# APM32F41x register map
File version: 1.0
CPU: CM4 r1p0, little endian, no MPU, no FPU, 3 interrupt priority bits
Registers are 32-bit, read-write, reset 0x0 unless marked. A register's access mark holds for its fields unless they carry their own. Offsets are from the block's base; [hi:lo] are bit positions; {n}, {i} and the like mark numbered series.

## DCI — Digital camera interface
Base 0x50050000
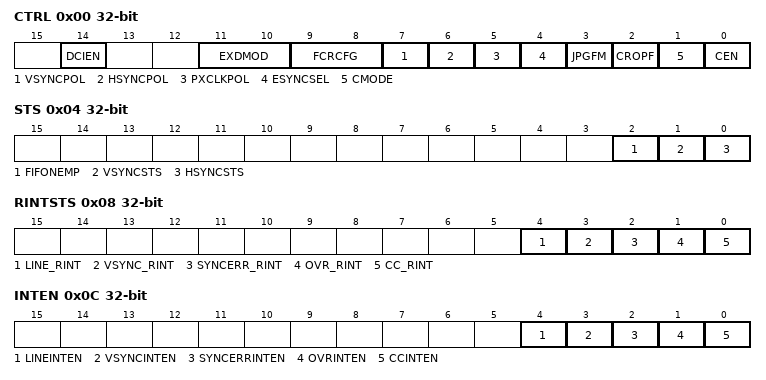
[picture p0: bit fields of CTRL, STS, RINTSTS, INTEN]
0x00 CTRL — control register 1
  [14] DCIEN — DCI enable
  [11:10] EXDMOD — Extended data mode
  [9:8] FCRCFG — Frame capture rate control
  [7] VSYNCPOL — Vertical synchronization polarity
  [6] HSYNCPOL — Horizontal synchronization polarity
  [5] PXCLKPOL — Pixel clock polarity
  [4] ESYNCSEL — Embedded synchronization select
  [3] JPGFM — JPEG format
  [2] CROPF — Crop feature
  [1] CMODE — Capture mode
  [0] CEN — Capture enable
0x04 STS ro — status register
  [2] FIFONEMP — FIFO not empty
  [1] VSYNCSTS
  [0] HSYNCSTS
0x08 RINTSTS ro — raw interrupt status register
  [4] LINE_RINT — Line raw interrupt status
  [3] VSYNC_RINT — VSYNC raw interrupt status
  [2] SYNCERR_RINT — Synchronization error raw interrupt status
  [1] OVR_RINT — Overrun raw interrupt status
  [0] CC_RINT — Capture complete raw interrupt status
0x0C INTEN — interrupt enable register
  [4] LINEINTEN — Line interrupt enable
  [3] VSYNCINTEN — VSYNC interrupt enable
  [2] SYNCERRINTEN — Synchronization error interrupt enable
  [1] OVRINTEN — Overrun interrupt enable
  [0] CCINTEN — Capture complete interrupt enable
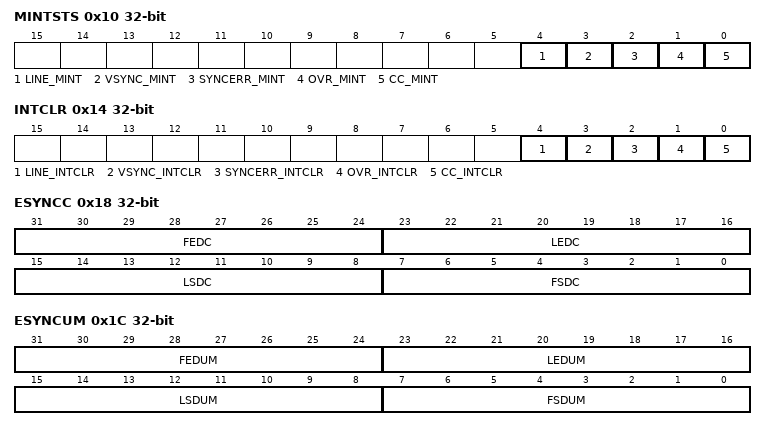
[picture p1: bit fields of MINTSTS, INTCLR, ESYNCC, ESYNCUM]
0x10 MINTSTS ro — masked interrupt status register
  [4] LINE_MINT — Line masked interrupt status
  [3] VSYNC_MINT — VSYNC masked interrupt status
  [2] SYNCERR_MINT — Synchronization error masked interrupt status
  [1] OVR_MINT — Overrun masked interrupt status
  [0] CC_MINT — Capture complete masked interrupt status
0x14 INTCLR wo — interrupt clear register
  [4] LINE_INTCLR — line interrupt status clear
  [3] VSYNC_INTCLR — Vertical synch interrupt status clear
  [2] SYNCERR_INTCLR — Synchronization error interrupt status clear
  [1] OVR_INTCLR — Overrun interrupt status clear
  [0] CC_INTCLR — Capture complete interrupt status clear
0x18 ESYNCC — embedded synchronization code register
  [31:24] FEDC — Frame end delimiter code
  [23:16] LEDC — Line end delimiter code
  [15:8] LSDC — Line start delimiter code
  [7:0] FSDC — Frame start delimiter code
0x1C ESYNCUM — embedded synchronization unmask register
  [31:24] FEDUM — Frame end delimiter unmask
  [23:16] LEDUM — Line end delimiter unmask
  [15:8] LSDUM — Line start delimiter unmask
  [7:0] FSDUM — Frame start delimiter unmask
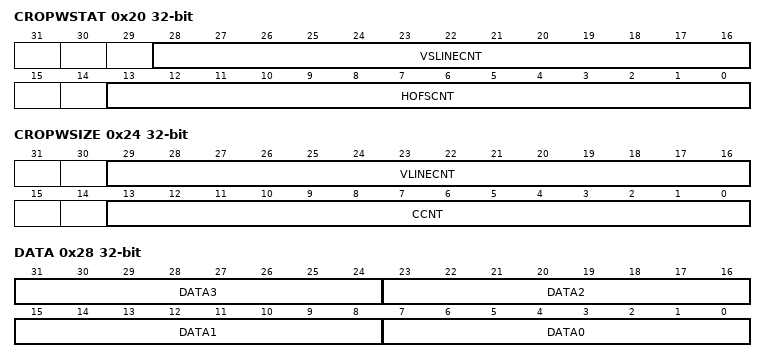
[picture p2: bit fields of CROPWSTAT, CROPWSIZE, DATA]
0x20 CROPWSTAT — crop window start
  [28:16] VSLINECNT — Vertical start line count
  [13:0] HOFSCNT — Horizontal offset count
0x24 CROPWSIZE — crop window size
  [29:16] VLINECNT — Vertical line count
  [13:0] CCNT — Capture count
0x28 DATA ro
  [8n+7:8n] DATA{n} (n=0..3) — Data byte {n}

## CRC — Cryptographic processor
Base 0x40023000
0x00 DATA reset 0xFFFFFFFF
0x04 INDATA — Independent Data register
  [7:0] INDATA
0x08 CTRL wo — Control register
  [0] RST — Reset CRC Calculation Unit

## GPIOI — General-purpose I/Os
Base 0x40022000
Same registers: GPIOC 0x40020800, GPIOD 0x40020C00, GPIOE 0x40021000, GPIOF 0x40021400, GPIOG 0x40021800, GPIOH 0x40021C00
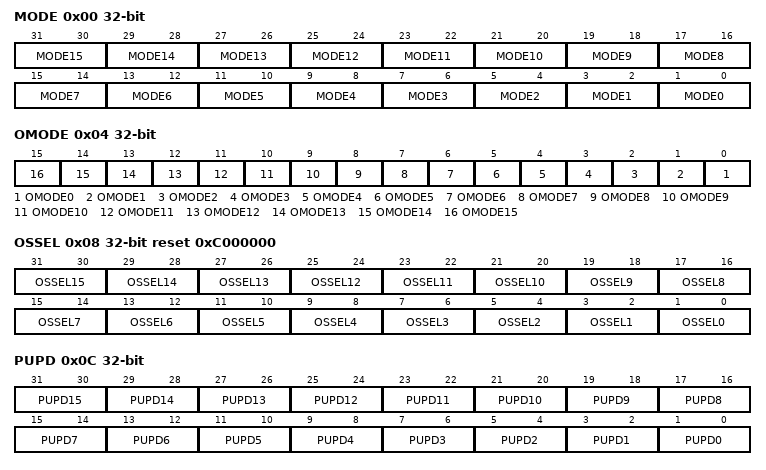
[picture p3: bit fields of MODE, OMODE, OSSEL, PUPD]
0x00 MODE — GPIO port mode register
  [2n+1:2n] MODE{n} (n=0..15) — Port x configuration bits (y = 0..15)
0x04 OMODE — GPIO port output type register
  [n] OMODE{n} (n=0..15) — Port x configuration bits (y = 0..15)
0x08 OSSEL reset 0xC000000 — GPIO port output speed register
  [2n+1:2n] OSSEL{n} (n=0..15) — Port x configuration bits (y = 0..15)
0x0C PUPD — GPIO port pull-up/pull-down register
  [2n+1:2n] PUPD{n} (n=0..15) — Port x configuration bits (y = 0..15)
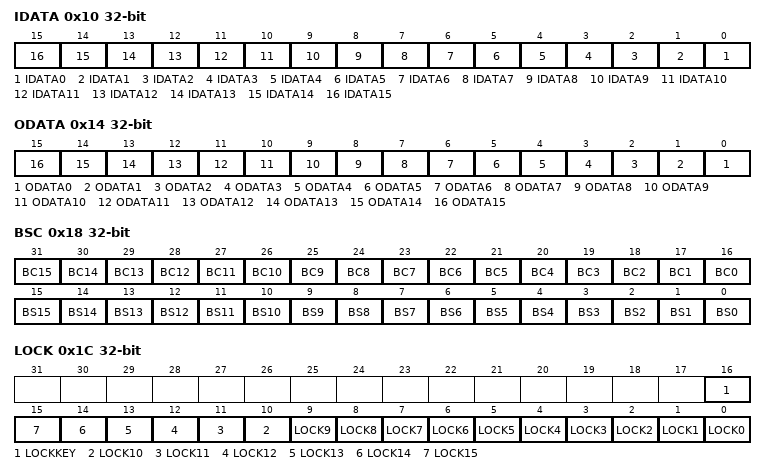
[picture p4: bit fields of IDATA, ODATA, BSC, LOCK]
0x10 IDATA ro — GPIO port input data register
  [n] IDATA{n} (n=0..15) — Port input data (y = 0..15)
0x14 ODATA — GPIO port output data register
  [n] ODATA{n} (n=0..15) — Port output data (y = 0..15)
0x18 BSC wo — GPIO port bit set/reset register
  [n+16] BC{n} (n=1..15) — Port x reset bit y (y = 0..15)
  [16] BC0 — Port x set bit y (y= 0..15)
  [n] BS{n} (n=0..15) — Port x set bit y (y= 0..15)
0x1C LOCK — GPIO port configuration lock register
  [16] LOCKKEY — Port x lock bit y (y= 0..15)
  [n] LOCK{n} (n=0..15) — Port x lock bit y (y= 0..15)
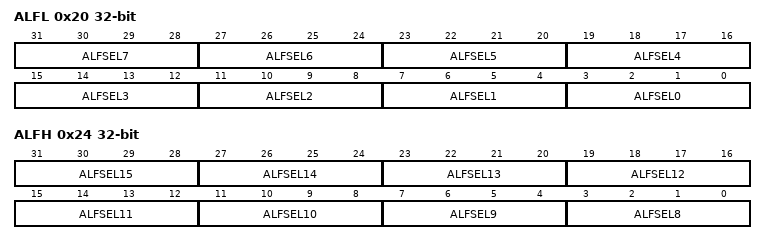
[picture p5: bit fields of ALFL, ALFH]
0x20 ALFL — GPIO alternate function low register
  [4n+3:4n] ALFSEL{n} (n=0..7) — Alternate function selection for port x bit y (y = 0..7)
0x24 ALFH — GPIO alternate function high register
  [4n-29:4n-32] ALFSEL{n} (n=8..15) — Alternate function selection for port x bit y (y = 8..15)

## GPIOB — General-purpose I/Os
Base 0x40020400
Registers as GPIOI; these are added or differ:
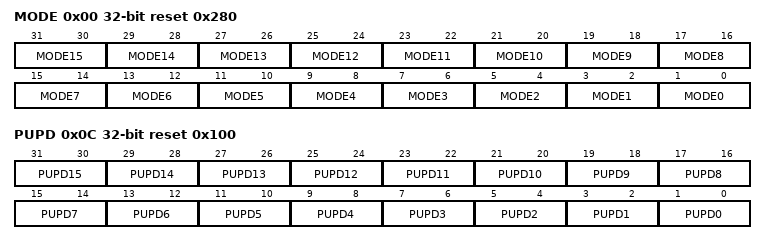
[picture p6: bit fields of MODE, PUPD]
0x00 MODE reset 0x280 — GPIO port mode register
  [2n+1:2n] MODE{n} (n=0..15) — Port x configuration bits (y = 0..15)
0x0C PUPD reset 0x100 — GPIO port pull-up/pull-down register
  [2n+1:2n] PUPD{n} (n=0..15) — Port x configuration bits (y = 0..15)

## GPIOA — General-purpose I/Os
Base 0x40020000
Registers as GPIOI; these are added or differ:
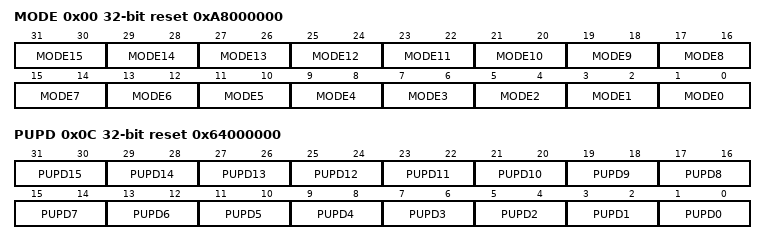
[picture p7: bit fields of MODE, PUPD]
0x00 MODE reset 0xA8000000 — GPIO port mode register
  [2n+1:2n] MODE{n} (n=0..15) — Port x configuration bits (y = 0..15)
0x0C PUPD reset 0x64000000 — GPIO port pull-up/pull-down register
  [2n+1:2n] PUPD{n} (n=0..15) — Port x configuration bits (y = 0..15)
